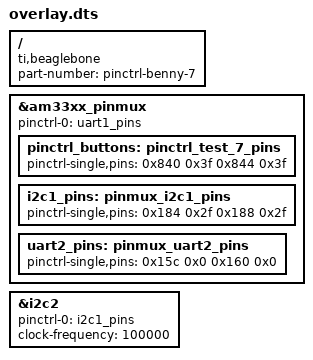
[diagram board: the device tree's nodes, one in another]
/dts-v1/;
/plugin/;

/ {
    compatible = "ti,beaglebone", "ti,beaglebone-green", "ti,beaglebone-black";
    part-number = "pinctrl-benny-7";

    /*Buttons 1-{P9_15 (GPIO_48) GPIO1_16}  2-{P9_23 (GPIO_49) GPIO1_17}*/
    fragment@0 {
        target = <&am33xx_pinmux>;
        __overlay__ {
            pinctrl_buttons: pinctrl_test_7_pins {
                pinctrl-single,pins = <
                    0x840 0x3f   /*P9_15 muxRegOffset,  INPUT | MODE7 */
					0x844 0x3f   /*P9_23 muxRegOffset,  INPUT | MODE7 */
                >;
            };
        };
    };
    /*I2C*/
    fragment@2 {
        target = <&i2c2>;  
        __overlay__ {
			pinctrl-names = "default";
			pinctrl-0 = <&i2c1_pins>;
            status = "okay";
            clock-frequency = <100000>; 
        };
    };
    /*UART*/
    fragment@3 {
        target = <&uart2>; 
        __overlay__ {
            status = "okay";
            pinctrl-names = "default";
            pinctrl-0 = <&uart1_pins>; 
        };
    };
	fragment@3 {
    	target = <&am33xx_pinmux>;
    	__overlay__ {
       		i2c1_pins: pinmux_i2c1_pins {
            	pinctrl-single,pins = <
                	0x184 0x2f /* P9_19, I2C1_SCL */
                	0x188 0x2f /* P9_20, I2C1_SDA */
            	>;
        	};
    	};
	};
	fragment@4 {
    	target = <&am33xx_pinmux>;
    	__overlay__ {
    	    uart2_pins: pinmux_uart2_pins {
    	        pinctrl-single,pins = <
    	            0x15c 0x0   /* P9_21, UART1_RXD */
    	            0x160 0x0   /* P9_22, UART1_TXD */
    	        >;
    	    };
    	};
	};
};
